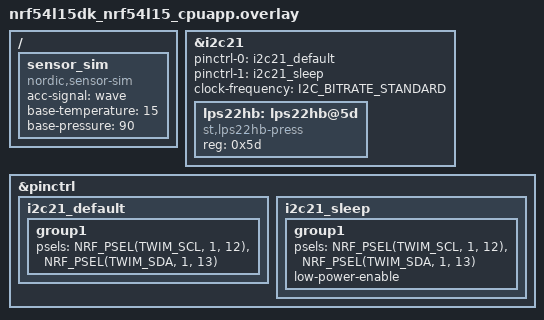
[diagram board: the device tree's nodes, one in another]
/ {
        sensor_sim: sensor_sim{
                compatible = "nordic,sensor-sim";
                acc-signal = "wave";
                base-temperature = < 15 >;
                base-pressure = < 90 >;
        };
};


&i2c21 {
	status = "okay";
	pinctrl-0 = <&i2c21_default>;
        pinctrl-1 = <&i2c21_sleep>;
	pinctrl-names = "default", "sleep";
	clock-frequency = <I2C_BITRATE_STANDARD>;

	lps22hb: lps22hb@5d{
		compatible = "st,lps22hb-press";
		reg = <0x5d>;
	};
};

&pinctrl {
         i2c21_default: i2c21_default {
                 group1  {
                         psels = <NRF_PSEL(TWIM_SCL, 1, 12)>,
                                 <NRF_PSEL(TWIM_SDA, 1, 13)>;
                 };
         };

           i2c21_sleep: i2c21_sleep {
                 group1  {
                         psels = <NRF_PSEL(TWIM_SCL, 1, 12)>,
                                 <NRF_PSEL(TWIM_SDA, 1, 13)>;
                         low-power-enable;
                 };
         };
};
